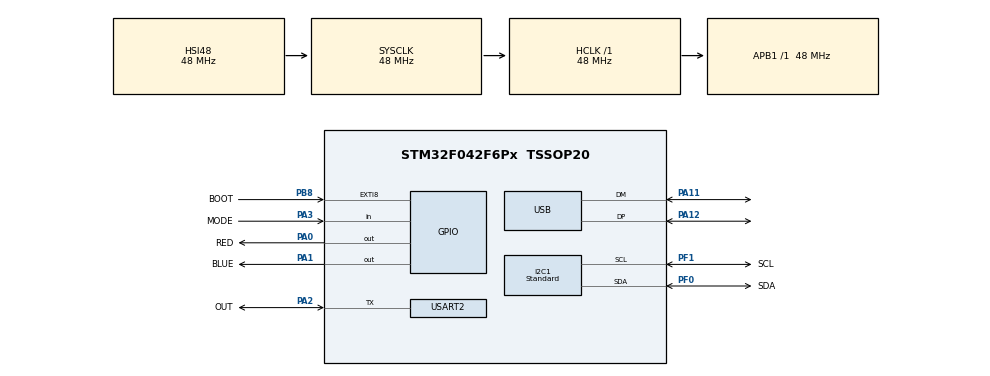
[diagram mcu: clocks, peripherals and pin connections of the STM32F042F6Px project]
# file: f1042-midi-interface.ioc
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I2C1.I2C_Speed_Mode=I2C_Standard
I2C1.OwnAddress=0x7e
I2C1.Timing=0x20303E5D
Mcu.Family=STM32F0
Mcu.Name=STM32F042F6Px
Mcu.Package=TSSOP20
NVIC.EXTI4_15_IRQn=true\:0\:0\:false\:false\:true
NVIC.I2C1_IRQn=true\:0\:0\:false\:false\:true
NVIC.TIM1_BRK_UP_TRG_COM_IRQn=true\:0\:0\:false\:false\:true
NVIC.TIM2_IRQn=true\:0\:0\:false\:false\:true
NVIC.TIM3_IRQn=true\:0\:0\:false\:false\:true
NVIC.USART2_IRQn=true\:0\:0\:false\:false\:true
NVIC.USB_IRQn=true\:3\:0\:true\:false\:true
PA0.GPIO_Label=RED
PA0.Signal=GPIO_Output
PA1.GPIO_Label=BLUE
PA1.Signal=GPIO_Output
PA11.Mode=Device
PA11.Signal=USB_DM
PA12.Mode=Device
PA12.Signal=USB_DP
PA2.GPIO_Label=OUT
PA2.Mode=Half_duplex(single_wire_mode)
PA2.Signal=USART2_TX
PA3.GPIO_Label=MODE
PA3.GPIO_PuPd=GPIO_PULLUP
PA3.Signal=GPIO_Input
PB8.GPIO_Label=BOOT
PB8.GPIO_ModeDefaultEXTI=GPIO_MODE_IT_RISING_FALLING
PB8.Signal=GPXTI8
PF0-OSC_IN.GPIO_Label=SDA
PF0-OSC_IN.Mode=I2C
PF0-OSC_IN.Signal=I2C1_SDA
PF1-OSC_OUT.GPIO_Label=SCL
PF1-OSC_OUT.Mode=I2C
PF1-OSC_OUT.Signal=I2C1_SCL
ProjectManager.HeapSize=0x200
ProjectManager.StackSize=0x400
ProjectManager.TargetToolchain=SW4STM32
RCC.AHBFreq_Value=48000000
RCC.APB1Freq_Value=48000000
RCC.APB1TimFreq_Value=48000000
RCC.HCLKFreq_Value=48000000
RCC.HSIState=RCC_HSI_ON
RCC.I2c1ClockSelection=RCC_I2C1CLKSOURCE_SYSCLK
RCC.INSTRUCTION_CACHE_ENABLE=0
RCC.PLLDivider=RCC_PREDIV_DIV2
RCC.PLLSourceVirtual=RCC_PLLSOURCE_HSI48
RCC.SYSCLKFreq_VALUE=48000000
RCC.SYSCLKSource=RCC_SYSCLKSOURCE_HSI48
RCC.VDD_VALUE=3.3
TIM1.Period=100
TIM1.Prescaler=48000
TIM2.Period=50
TIM2.Prescaler=48000
TIM3.Period=10
TIM3.Prescaler=48000
USART2.BaudRate=31250
USB_DEVICE.USBD_HandleTypeDef=hUsbDeviceFS
USB_DEVICE.VirtualMode=Audio
VP_SYS_VS_PINREMAP.Mode=PINREMAP
VP_TIM1_VS_ClockSourceINT.Mode=Internal
VP_TIM2_VS_ClockSourceINT.Mode=Internal
VP_TIM3_VS_ClockSourceINT.Mode=Internal
VP_USB_DEVICE_VS_USB_DEVICE_AUDIO_FS.Mode=AUDIO_FS
board=f1042-midi-interface

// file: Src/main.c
/**
  ******************************************************************************
  * File Name          : main.c
  * Description        : Main program body
  ******************************************************************************
  *
  * COPYRIGHT(c) 2016 STMicroelectronics
  *
  * Redistribution and use in source and binary forms, with or without modification,
  * are permitted provided that the following conditions are met:
  *   1. Redistributions of source code must retain the above copyright notice,
  *      this list of conditions and the following disclaimer.
  *   2. Redistributions in binary form must reproduce the above copyright notice,
  *      this list of conditions and the following disclaimer in the documentation
  *      and/or other materials provided with the distribution.
  *   3. Neither the name of STMicroelectronics nor the names of its contributors
  *      may be used to endorse or promote products derived from this software
  *      without specific prior written permission.
  *
  * THIS SOFTWARE IS PROVIDED BY THE COPYRIGHT HOLDERS AND CONTRIBUTORS "AS IS"
  * AND ANY EXPRESS OR IMPLIED WARRANTIES, INCLUDING, BUT NOT LIMITED TO, THE
  * IMPLIED WARRANTIES OF MERCHANTABILITY AND FITNESS FOR A PARTICULAR PURPOSE ARE
  * DISCLAIMED. IN NO EVENT SHALL THE COPYRIGHT HOLDER OR CONTRIBUTORS BE LIABLE
  * FOR ANY DIRECT, INDIRECT, INCIDENTAL, SPECIAL, EXEMPLARY, OR CONSEQUENTIAL
  * DAMAGES (INCLUDING, BUT NOT LIMITED TO, PROCUREMENT OF SUBSTITUTE GOODS OR
  * SERVICES; LOSS OF USE, DATA, OR PROFITS; OR BUSINESS INTERRUPTION) HOWEVER
  * CAUSED AND ON ANY THEORY OF LIABILITY, WHETHER IN CONTRACT, STRICT LIABILITY,
  * OR TORT (INCLUDING NEGLIGENCE OR OTHERWISE) ARISING IN ANY WAY OUT OF THE USE
  * OF THIS SOFTWARE, EVEN IF ADVISED OF THE POSSIBILITY OF SUCH DAMAGE.
  *
  ******************************************************************************
  */
#include "stm32f0xx_hal.h"
#include "usb_device.h"

/* USER CODE BEGIN Includes */
#include <app_task.h>
#include <application.h>
//#include <usb_device.h>
/* USER CODE END Includes */

I2C_HandleTypeDef hi2c1;

TIM_HandleTypeDef htim1;
TIM_HandleTypeDef htim2;
TIM_HandleTypeDef htim3;

UART_HandleTypeDef huart2;

/* USER CODE BEGIN PV */
/* Private variables ---------------------------------------------------------*/

/* USER CODE END PV */

void SystemClock_Config(void);
void Error_Handler(void);
static void MX_GPIO_Init(void);
static void MX_TIM1_Init(void);
static void MX_USART2_UART_Init(void);
static void MX_TIM3_Init(void);
static void MX_I2C1_Init(void);
static void MX_TIM2_Init(void);

/* USER CODE BEGIN PFP */
/* Private function prototypes -----------------------------------------------*/

/* USER CODE END PFP */

int main(void)
{

  /* MCU Configuration----------------------------------------------------------*/

  /* Reset of all peripherals, Initializes the Flash interface and the Systick. */
  HAL_Init();

  /* Configure the system clock */
  SystemClock_Config();

  /* Initialize all configured peripherals */
  MX_GPIO_Init();
  MX_TIM1_Init();
  MX_USB_DEVICE_Init();
  MX_USART2_UART_Init();
  MX_TIM3_Init();
  MX_I2C1_Init();
  MX_TIM2_Init();

  /* Infinite loop */
  /* USER CODE BEGIN WHILE */
	application_run();
  /* USER CODE END WHILE */

}

/** System Clock Configuration
*/
void SystemClock_Config(void)
{

  RCC_OscInitTypeDef RCC_OscInitStruct;
  RCC_ClkInitTypeDef RCC_ClkInitStruct;
  RCC_PeriphCLKInitTypeDef PeriphClkInit;

  RCC_OscInitStruct.OscillatorType = RCC_OSCILLATORTYPE_HSI48;
  RCC_OscInitStruct.HSI48State = RCC_HSI48_ON;
  RCC_OscInitStruct.PLL.PLLState = RCC_PLL_NONE;
  if (HAL_RCC_OscConfig(&RCC_OscInitStruct) != HAL_OK)
  {
    Error_Handler();
  }

  RCC_ClkInitStruct.ClockType = RCC_CLOCKTYPE_HCLK|RCC_CLOCKTYPE_SYSCLK
                              |RCC_CLOCKTYPE_PCLK1;
  RCC_ClkInitStruct.SYSCLKSource = RCC_SYSCLKSOURCE_HSI48;
  RCC_ClkInitStruct.AHBCLKDivider = RCC_SYSCLK_DIV1;
  RCC_ClkInitStruct.APB1CLKDivider = RCC_HCLK_DIV1;
  if (HAL_RCC_ClockConfig(&RCC_ClkInitStruct, FLASH_LATENCY_1) != HAL_OK)
  {
    Error_Handler();
  }

  PeriphClkInit.PeriphClockSelection = RCC_PERIPHCLK_USB|RCC_PERIPHCLK_I2C1;
  PeriphClkInit.I2c1ClockSelection = RCC_I2C1CLKSOURCE_SYSCLK;
  PeriphClkInit.UsbClockSelection = RCC_USBCLKSOURCE_HSI48;
  if (HAL_RCCEx_PeriphCLKConfig(&PeriphClkInit) != HAL_OK)
  {
    Error_Handler();
  }

  HAL_SYSTICK_Config(HAL_RCC_GetHCLKFreq()/1000);

  HAL_SYSTICK_CLKSourceConfig(SYSTICK_CLKSOURCE_HCLK);

  /* SysTick_IRQn interrupt configuration */
  HAL_NVIC_SetPriority(SysTick_IRQn, 2, 0);
}

/* I2C1 init function */
static void MX_I2C1_Init(void)
{

  hi2c1.Instance = I2C1;
  hi2c1.Init.Timing = 0x20303E5D;
  hi2c1.Init.OwnAddress1 = 252;
  hi2c1.Init.AddressingMode = I2C_ADDRESSINGMODE_7BIT;
  hi2c1.Init.DualAddressMode = I2C_DUALADDRESS_DISABLE;
  hi2c1.Init.OwnAddress2 = 0;
  hi2c1.Init.OwnAddress2Masks = I2C_OA2_NOMASK;
  hi2c1.Init.GeneralCallMode = I2C_GENERALCALL_DISABLE;
  hi2c1.Init.NoStretchMode = I2C_NOSTRETCH_DISABLE;
  if (HAL_I2C_Init(&hi2c1) != HAL_OK)
  {
    Error_Handler();
  }

    /**Configure Analogue filter
    */
  if (HAL_I2CEx_ConfigAnalogFilter(&hi2c1, I2C_ANALOGFILTER_ENABLE) != HAL_OK)
  {
    Error_Handler();
  }

}

/* TIM1 init function */
static void MX_TIM1_Init(void)
{

  TIM_ClockConfigTypeDef sClockSourceConfig;
  TIM_MasterConfigTypeDef sMasterConfig;

  htim1.Instance = TIM1;
  htim1.Init.Prescaler = 48000;
  htim1.Init.CounterMode = TIM_COUNTERMODE_UP;
  htim1.Init.Period = 100;
  htim1.Init.ClockDivision = TIM_CLOCKDIVISION_DIV1;
  htim1.Init.RepetitionCounter = 0;
  if (HAL_TIM_Base_Init(&htim1) != HAL_OK)
  {
    Error_Handler();
  }

  sClockSourceConfig.ClockSource = TIM_CLOCKSOURCE_INTERNAL;
  if (HAL_TIM_ConfigClockSource(&htim1, &sClockSourceConfig) != HAL_OK)
  {
    Error_Handler();
  }

  sMasterConfig.MasterOutputTrigger = TIM_TRGO_RESET;
  sMasterConfig.MasterSlaveMode = TIM_MASTERSLAVEMODE_DISABLE;
  if (HAL_TIMEx_MasterConfigSynchronization(&htim1, &sMasterConfig) != HAL_OK)
  {
    Error_Handler();
  }

}

/* TIM2 init function */
static void MX_TIM2_Init(void)
{

  TIM_ClockConfigTypeDef sClockSourceConfig;
  TIM_MasterConfigTypeDef sMasterConfig;

  htim2.Instance = TIM2;
  htim2.Init.Prescaler = 48000;
  htim2.Init.CounterMode = TIM_COUNTERMODE_UP;
  htim2.Init.Period = 50;
  htim2.Init.ClockDivision = TIM_CLOCKDIVISION_DIV1;
  if (HAL_TIM_Base_Init(&htim2) != HAL_OK)
  {
    Error_Handler();
  }

  sClockSourceConfig.ClockSource = TIM_CLOCKSOURCE_INTERNAL;
  if (HAL_TIM_ConfigClockSource(&htim2, &sClockSourceConfig) != HAL_OK)
  {
    Error_Handler();
  }

  sMasterConfig.MasterOutputTrigger = TIM_TRGO_RESET;
  sMasterConfig.MasterSlaveMode = TIM_MASTERSLAVEMODE_DISABLE;
  if (HAL_TIMEx_MasterConfigSynchronization(&htim2, &sMasterConfig) != HAL_OK)
  {
    Error_Handler();
  }

}

/* TIM3 init function */
static void MX_TIM3_Init(void)
{

  TIM_ClockConfigTypeDef sClockSourceConfig;
  TIM_MasterConfigTypeDef sMasterConfig;

  htim3.Instance = TIM3;
  htim3.Init.Prescaler = 48000;
  htim3.Init.CounterMode = TIM_COUNTERMODE_UP;
  htim3.Init.Period = 10;
  htim3.Init.ClockDivision = TIM_CLOCKDIVISION_DIV1;
  if (HAL_TIM_Base_Init(&htim3) != HAL_OK)
  {
    Error_Handler();
  }

  sClockSourceConfig.ClockSource = TIM_CLOCKSOURCE_INTERNAL;
  if (HAL_TIM_ConfigClockSource(&htim3, &sClockSourceConfig) != HAL_OK)
  {
    Error_Handler();
  }

  sMasterConfig.MasterOutputTrigger = TIM_TRGO_RESET;
  sMasterConfig.MasterSlaveMode = TIM_MASTERSLAVEMODE_DISABLE;
  if (HAL_TIMEx_MasterConfigSynchronization(&htim3, &sMasterConfig) != HAL_OK)
  {
    Error_Handler();
  }

}

/* USART2 init function */
static void MX_USART2_UART_Init(void)
{

  huart2.Instance = USART2;
  huart2.Init.BaudRate = 31250;
  huart2.Init.WordLength = UART_WORDLENGTH_7B;
  huart2.Init.StopBits = UART_STOPBITS_1;
  huart2.Init.Parity = UART_PARITY_NONE;
  huart2.Init.Mode = UART_MODE_TX_RX;
  huart2.Init.HwFlowCtl = UART_HWCONTROL_NONE;
  huart2.Init.OverSampling = UART_OVERSAMPLING_16;
  huart2.Init.OneBitSampling = UART_ONE_BIT_SAMPLE_DISABLE;
  huart2.AdvancedInit.AdvFeatureInit = UART_ADVFEATURE_NO_INIT;
  if (HAL_HalfDuplex_Init(&huart2) != HAL_OK)
  {
    Error_Handler();
  }

}

/** Configure pins as
        * Analog
        * Input
        * Output
        * EVENT_OUT
        * EXTI
*/
static void MX_GPIO_Init(void)
{

  GPIO_InitTypeDef GPIO_InitStruct;

  /* GPIO Ports Clock Enable */
  __HAL_RCC_GPIOB_CLK_ENABLE();
  __HAL_RCC_GPIOF_CLK_ENABLE();
  __HAL_RCC_GPIOA_CLK_ENABLE();

  /*Configure GPIO pin : BOOT_Pin */
  GPIO_InitStruct.Pin = BOOT_Pin;
  GPIO_InitStruct.Mode = GPIO_MODE_IT_RISING_FALLING;
  GPIO_InitStruct.Pull = GPIO_NOPULL;
  HAL_GPIO_Init(BOOT_GPIO_Port, &GPIO_InitStruct);

  /*Configure GPIO pins : RED_Pin BLUE_Pin */
  GPIO_InitStruct.Pin = RED_Pin|BLUE_Pin;
  GPIO_InitStruct.Mode = GPIO_MODE_OUTPUT_PP;
  GPIO_InitStruct.Pull = GPIO_NOPULL;
  GPIO_InitStruct.Speed = GPIO_SPEED_FREQ_LOW;
  HAL_GPIO_Init(GPIOA, &GPIO_InitStruct);

  /*Configure GPIO pin : MODE_Pin */
  GPIO_InitStruct.Pin = MODE_Pin;
  GPIO_InitStruct.Mode = GPIO_MODE_INPUT;
  GPIO_InitStruct.Pull = GPIO_PULLUP;
  HAL_GPIO_Init(MODE_GPIO_Port, &GPIO_InitStruct);

  /*Configure GPIO pin Output Level */
  HAL_GPIO_WritePin(GPIOA, RED_Pin|BLUE_Pin, GPIO_PIN_RESET);

  /* EXTI interrupt init*/
  HAL_NVIC_SetPriority(EXTI4_15_IRQn, 0, 0);
  HAL_NVIC_EnableIRQ(EXTI4_15_IRQn);

}

void Error_Handler(void)
{
  /* USER CODE BEGIN Error_Handler */
	HAL_GPIO_WritePin(BLUE_GPIO_Port, BLUE_Pin, GPIO_PIN_SET);
	HAL_GPIO_WritePin(BLUE_GPIO_Port, RED_Pin, GPIO_PIN_SET);
	/* User can add his own implementation to report the HAL error return state */
	while (1) {
	}
  /* USER CODE END Error_Handler */
}

/************************ (C) COPYRIGHT STMicroelectronics *****END OF FILE****/
